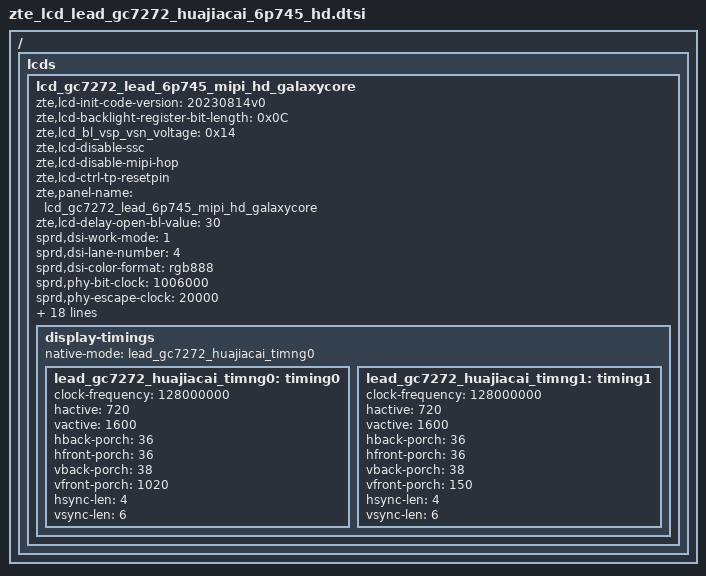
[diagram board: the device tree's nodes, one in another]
/ {
	fragment {
		target-path = "/";
		__overlay__ {
lcds {
		lcd_gc7272_lead_6p745_mipi_hd_galaxycore: lcd_gc7272_lead_6p745_mipi_hd_galaxycore {
			zte,lcd-init-code-version = "20230814v0";
			zte,lcd-backlight-register-bit-length = <0x0C>;
			zte,lcd_bl_vsp_vsn_voltage = <0x14>;
			zte,lcd-disable-ssc;
			zte,lcd-disable-mipi-hop;
			zte,lcd-ctrl-tp-resetpin;
			zte,panel-name = "lcd_gc7272_lead_6p745_mipi_hd_galaxycore";
			zte,lcd-delay-open-bl-value = <30>;

			sprd,dsi-work-mode = <1>; /* video burst mode*/
			sprd,dsi-lane-number = <4>;
			sprd,dsi-color-format = "rgb888";

			sprd,phy-bit-clock = <1006000>;	/* kbps */
			sprd,phy-escape-clock = <20000>;/* kHz */

			/*sprd,video-lp-cmd-enable = <1>;
			sprd,hporch-lp-disable = <1>;
			sprd,dpi-clk-div = <6>;*/

			sprd,width-mm = <70308>;
			sprd,height-mm = <156240>;

			sprd,esd-check-enable = <1>;/* 0:close , 1:open */
			sprd,esd-check-mode = <1>;/* 0:REG ,1:TE  */
			sprd,esd-check-period = <2000>;
			sprd,esd-check-register = <0x0A>;
			sprd,esd-check-value = <0x9C>;

			sprd,reset-on-sequence = <1 5>, <0 5>, <1 5>, <0 5>, <1 5>, <0 5>, <1 5>, <0 5>, <1 30>;
			sprd,reset-off-sequence = <1 5>;

			//sprd,use-dcs-write;
			sprd,initial-command = [
39 00 00 04 ff 55 aa 66 
39 00 00 02 ff 10 
39 00 00 02 fb 00 
39 00 00 02 ff 20 
39 00 00 02 fb 00 
39 00 00 02 ff 21 
39 00 00 02 fb 00 
39 00 00 02 ff 22 
39 00 00 02 fb 00 
39 00 00 02 ff 23 
39 00 00 02 fb 00 
39 00 00 02 ff 24 
39 00 00 02 fb 00 
39 00 00 02 ff 27 
39 00 00 02 fb 00 
39 00 00 02 ff 26 
39 00 00 02 fb 00 
39 00 00 02 ff 28 
39 00 00 02 fb 00 
39 00 00 02 ff b3 
39 00 00 02 fb 00 
39 00 00 02 ff 20 
39 00 00 02 2d aa 
39 00 00 02 a3 13
39 00 00 02 a7 13
39 00 00 02 ff b3 
39 00 00 02 4e 45 
39 00 00 02 2b 43 
39 00 00 02 3f 37 
39 00 00 02 50 10 
39 00 00 02 ff 20 
39 00 00 02 29 e0
39 00 00 02 20 84 
39 00 00 02 21 00 
39 00 00 02 22 80 
39 00 00 02 2e 00
39 00 00 02 ff a3 
39 00 00 02 58 aa 
39 00 00 02 5c 00 
39 00 00 02 62 80 
39 00 00 02 ff 26 
39 00 00 02 43 00 
39 00 00 02 ff 22 
39 00 00 02 0e 33 
39 00 00 02 0c 01 
39 00 00 02 0b 6a 
39 00 00 02 ff 28 
39 00 00 02 7d 1f 
39 00 00 02 7b 40 
39 00 00 02 ff 22 
39 00 00 02 e4 00 
39 00 00 02 01 06 
39 00 00 02 02 40 
39 00 00 02 03 00 
39 00 00 02 ff 20 
39 00 00 02 c3 00 
39 00 00 02 c4 69 
39 00 00 02 c5 00 
39 00 00 02 c6 69 
39 00 00 02 b3 00 
39 00 00 02 b4 20 
39 00 00 02 b5 00 
39 00 00 02 b6 dc 
39 00 00 02 d3 24 
39 00 00 02 ff 22
39 00 00 02 25 18
39 00 00 02 26 00
39 00 00 02 2e 9a
39 00 00 02 2f 00
39 00 00 02 36 1a
39 00 00 02 37 00
39 00 00 02 3f 9a
39 00 00 02 40 00
39 00 00 02 ff 28
39 00 00 02 01 25
39 00 00 02 02 04
39 00 00 02 03 06
39 00 00 02 04 25 
39 00 00 02 05 25 
39 00 00 02 06 25 
39 00 00 02 07 25 
39 00 00 02 08 25
39 00 00 02 09 19
39 00 00 02 0a 18
39 00 00 02 0b 23
39 00 00 02 0c 28
39 00 00 02 0d 13
39 00 00 02 0e 0b
39 00 00 02 0f 12
39 00 00 02 10 0a
39 00 00 02 11 11
39 00 00 02 12 09 
39 00 00 02 13 10 
39 00 00 02 14 08 
39 00 00 02 15 02 
39 00 00 02 16 00 
39 00 00 02 17 25 
39 00 00 02 18 05 
39 00 00 02 19 07 
39 00 00 02 1a 25 
39 00 00 02 1b 25 
39 00 00 02 1c 25 
39 00 00 02 1d 25 
39 00 00 02 1e 25
39 00 00 02 1f 19
39 00 00 02 20 18
39 00 00 02 21 23
39 00 00 02 22 29
39 00 00 02 23 17
39 00 00 02 24 0f
39 00 00 02 25 16 
39 00 00 02 26 0e 
39 00 00 02 27 15 
39 00 00 02 28 0d 
39 00 00 02 29 14 
39 00 00 02 2a 0c 
39 00 00 02 2b 03 
39 00 00 02 2d 01 
39 00 00 02 30 00 
39 00 00 02 31 00 
39 00 00 02 32 00 
39 00 00 02 33 00 
39 00 00 02 34 00 
39 00 00 02 35 00 
39 00 00 02 36 00 
39 00 00 02 37 00 
39 00 00 02 2f 1e
39 00 00 02 ff 21
39 00 00 02 7e 0f
39 00 00 02 7f 23
39 00 00 02 8b 23
39 00 00 02 97 23
39 00 00 02 a3 23
39 00 00 02 80 03
39 00 00 02 8c 02
39 00 00 02 98 01
39 00 00 02 a4 00
39 00 00 02 81 00
39 00 00 02 8d 01
39 00 00 02 99 02
39 00 00 02 a5 03
39 00 00 02 af 40
39 00 00 02 b0 40
39 00 00 02 b1 40
39 00 00 02 b2 40
39 00 00 02 2b 00
39 00 00 02 83 01
39 00 00 02 8f 01
39 00 00 02 9b 01
39 00 00 02 a7 01
39 00 00 02 84 52
39 00 00 02 90 52
39 00 00 02 9c 52
39 00 00 02 a8 52
39 00 00 02 85 60
39 00 00 02 91 60
39 00 00 02 9d 60
39 00 00 02 a9 60
39 00 00 02 87 0b
39 00 00 02 93 0c
39 00 00 02 9f 0d
39 00 00 02 ab 0e
39 00 00 02 82 a3 
39 00 00 02 8e a3 
39 00 00 02 9a a3 
39 00 00 02 a6 a3 
39 00 00 02 2e 00 
39 00 00 02 88 b7 
39 00 00 02 89 20 
39 00 00 02 8a 23 
39 00 00 02 94 b7 
39 00 00 02 95 20 
39 00 00 02 96 23 
39 00 00 02 a0 b7 
39 00 00 02 a1 20 
39 00 00 02 a2 23 
39 00 00 02 ac b7 
39 00 00 02 ad 20 
39 00 00 02 ae 23 
39 00 00 02 45 ff 
39 00 00 02 46 a9 
39 00 00 02 4c a9 
39 00 00 02 52 a9 
39 00 00 02 58 a9
39 00 00 02 5e a4
39 00 00 02 64 a4
39 00 00 02 6a a4
39 00 00 02 70 a4
39 00 00 02 47 0a
39 00 00 02 4d 09
39 00 00 02 53 06
39 00 00 02 59 05
39 00 00 02 48 60
39 00 00 02 4e 27
39 00 00 02 54 26
39 00 00 02 5a 25
39 00 00 02 5f 25
39 00 00 02 65 26
39 00 00 02 6b 27
39 00 00 02 71 60
39 00 00 02 60 05
39 00 00 02 66 06
39 00 00 02 6c 09
39 00 00 02 72 0a
39 00 00 02 76 40
39 00 00 02 77 40
39 00 00 02 78 40
39 00 00 02 79 40
39 00 00 02 7a 40
39 00 00 02 7b 40
39 00 00 02 7c 40
39 00 00 02 7d 40
39 00 00 02 49 5d
39 00 00 02 4a 5d
39 00 00 02 4f 5d
39 00 00 02 50 5d
39 00 00 02 55 5d
39 00 00 02 56 5d
39 00 00 02 5b 5d
39 00 00 02 5c 5d
39 00 00 02 61 5d
39 00 00 02 62 5d
39 00 00 02 67 5d
39 00 00 02 68 5d
39 00 00 02 6d 5d
39 00 00 02 6e 5d
39 00 00 02 73 5d
39 00 00 02 74 5d
39 00 00 02 be 03
39 00 00 02 c0 72
39 00 00 02 c1 70
39 00 00 02 bf aa
39 00 00 02 ff 25
39 00 00 02 19 03
39 00 00 02 1a a9
39 00 00 02 20 a9
39 00 00 02 1b 64
39 00 00 02 21 65
39 00 00 02 1c 65
39 00 00 02 22 64
39 00 00 02 33 40
39 00 00 02 34 40
39 00 00 02 1d 5d
39 00 00 02 1e 5d
39 00 00 02 23 5d
39 00 00 02 24 5d
39 00 00 02 ff 22
39 00 00 02 05 00
39 00 00 02 08 22
39 00 00 02 ff 28
39 00 00 02 3d 5c
39 00 00 02 3e 5c
39 00 00 02 3f 3c
39 00 00 02 40 3c
39 00 00 02 45 50
39 00 00 02 46 50
39 00 00 02 47 30 
39 00 00 02 48 30 
39 00 00 02 4d a2 
39 00 00 02 50 aa 
39 00 00 02 52 71 
39 00 00 02 53 22 
39 00 00 02 56 12 
39 00 00 02 57 20 
39 00 00 02 5a 85
39 00 00 02 5b 85
39 00 00 02 ff 20 
39 00 00 02 7e 03 
39 00 00 02 7f 00 
39 00 00 02 80 64 
39 00 00 02 81 00 
39 00 00 02 82 00 
39 00 00 02 83 64 
39 00 00 02 84 64 
39 00 00 02 85 2a 
39 00 00 02 86 56 
39 00 00 02 87 2a 
39 00 00 02 88 56 
39 00 00 02 8a 0a 
39 00 00 02 8b 0a 
39 00 00 02 ff 25 
39 00 00 02 75 00 
39 00 00 02 76 00 
39 00 00 02 77 64 
39 00 00 02 78 00 
39 00 00 02 79 64 
39 00 00 02 7a 64 
39 00 00 02 7b 64 
39 00 00 02 7c 21 
39 00 00 02 7d 44 
39 00 00 02 7e 21 
39 00 00 02 7f 44 
39 00 00 02 80 00 
39 00 00 02 81 03 
39 00 00 02 82 03 
39 00 00 02 ff 23 
39 00 00 02 29 03 
39 00 00 11 01 00 00 00 03 00 4a 00 60 00 79 00 88 00 9c 00 aa
39 00 00 11 02 00 C6 00 FD 01 20 01 55 01 79 01 B4 01 E1 01 E3
39 00 00 11 03 02 17 02 59 02 80 02 BA 02 E0 03 10 03 28 03 38
39 00 00 0D 04 03 48 03 5D 03 73 03 9F 03 CD 03 FF
39 00 00 11 0d 00 00 00 03 00 4a 00 60 00 79 00 88 00 9c 00 aa
39 00 00 11 0E 00 C6 00 FD 01 20 01 55 01 79 01 B4 01 E1 01 E3
39 00 00 11 0F 02 17 02 59 02 80 02 BA 02 E0 03 10 03 28 03 38
39 00 00 0D 10 03 48 03 5D 03 73 03 9F 03 CD 03 FF
39 00 00 02 ff b3
39 00 00 02 1e 26
39 00 00 02 ff 20
39 00 00 02 56 bf
39 00 00 02 57 17
39 00 00 02 58 32
39 00 00 02 59 32
39 00 00 02 ff b3
39 00 00 02 31 08
39 00 00 02 2e 00
39 00 00 02 47 01
39 00 00 02 C6 A0
39 00 00 02 7a 06
39 00 00 02 7b f2
39 00 00 02 ff 20
39 00 00 02 f5 e0
39 00 00 02 f6 0b
39 00 00 02 ff 20
39 00 00 02 15 0F
39 00 00 02 16 A0
39 00 00 02 17 0B
39 00 00 02 18 B8
39 00 00 02 19 07
39 00 00 02 1A D0
39 00 00 02 1B 03
39 00 00 02 1C E8
39 00 00 02 ff 10
/*
39 00 00 03 51 00 00
39 00 00 02 53 2c
39 00 00 02 55 00
*/
39 00 00 02 36 08
39 00 00 02 69 00
39 00 00 02 35 00
05 78 00 01 11
05 32 00 01 29
];

sprd,sleep-in-command = [
39 00 00 04 ff 55 aa 66
39 00 00 02 ff 10
15 32 00 01 28
15 78 00 01 10
39 20 00 02 4f 01
];
sprd,sleep-in-command2 = [
39 00 00 04 ff 55 aa 66
39 00 00 02 ff 10
15 32 00 01 28
15 78 00 01 10
];

			sprd,sleep-out-command = [
				15 78 00 01 11
				15 32 00 01 29
				];

			display-timings {
				native-mode = <&lead_gc7272_huajiacai_timng0>;
				lead_gc7272_huajiacai_timng0: timing0 {
					clock-frequency = <128000000>;
					hactive = <720>;
					vactive = <1600>;
					hback-porch = <36>;
					hfront-porch = <36>;
					vback-porch = <38>;
					vfront-porch = <1020>;
					hsync-len = <4>;
					vsync-len = <6>;
				};
				lead_gc7272_huajiacai_timng1: timing1 {
					clock-frequency = <128000000>;
					hactive = <720>;
					vactive = <1600>;
					hback-porch = <36>;
					hfront-porch = <36>;
					vback-porch = <38>;
					vfront-porch = <150>;
					hsync-len = <4>;
					vsync-len = <6>;
				};
			};
		};
	};
};
};};

